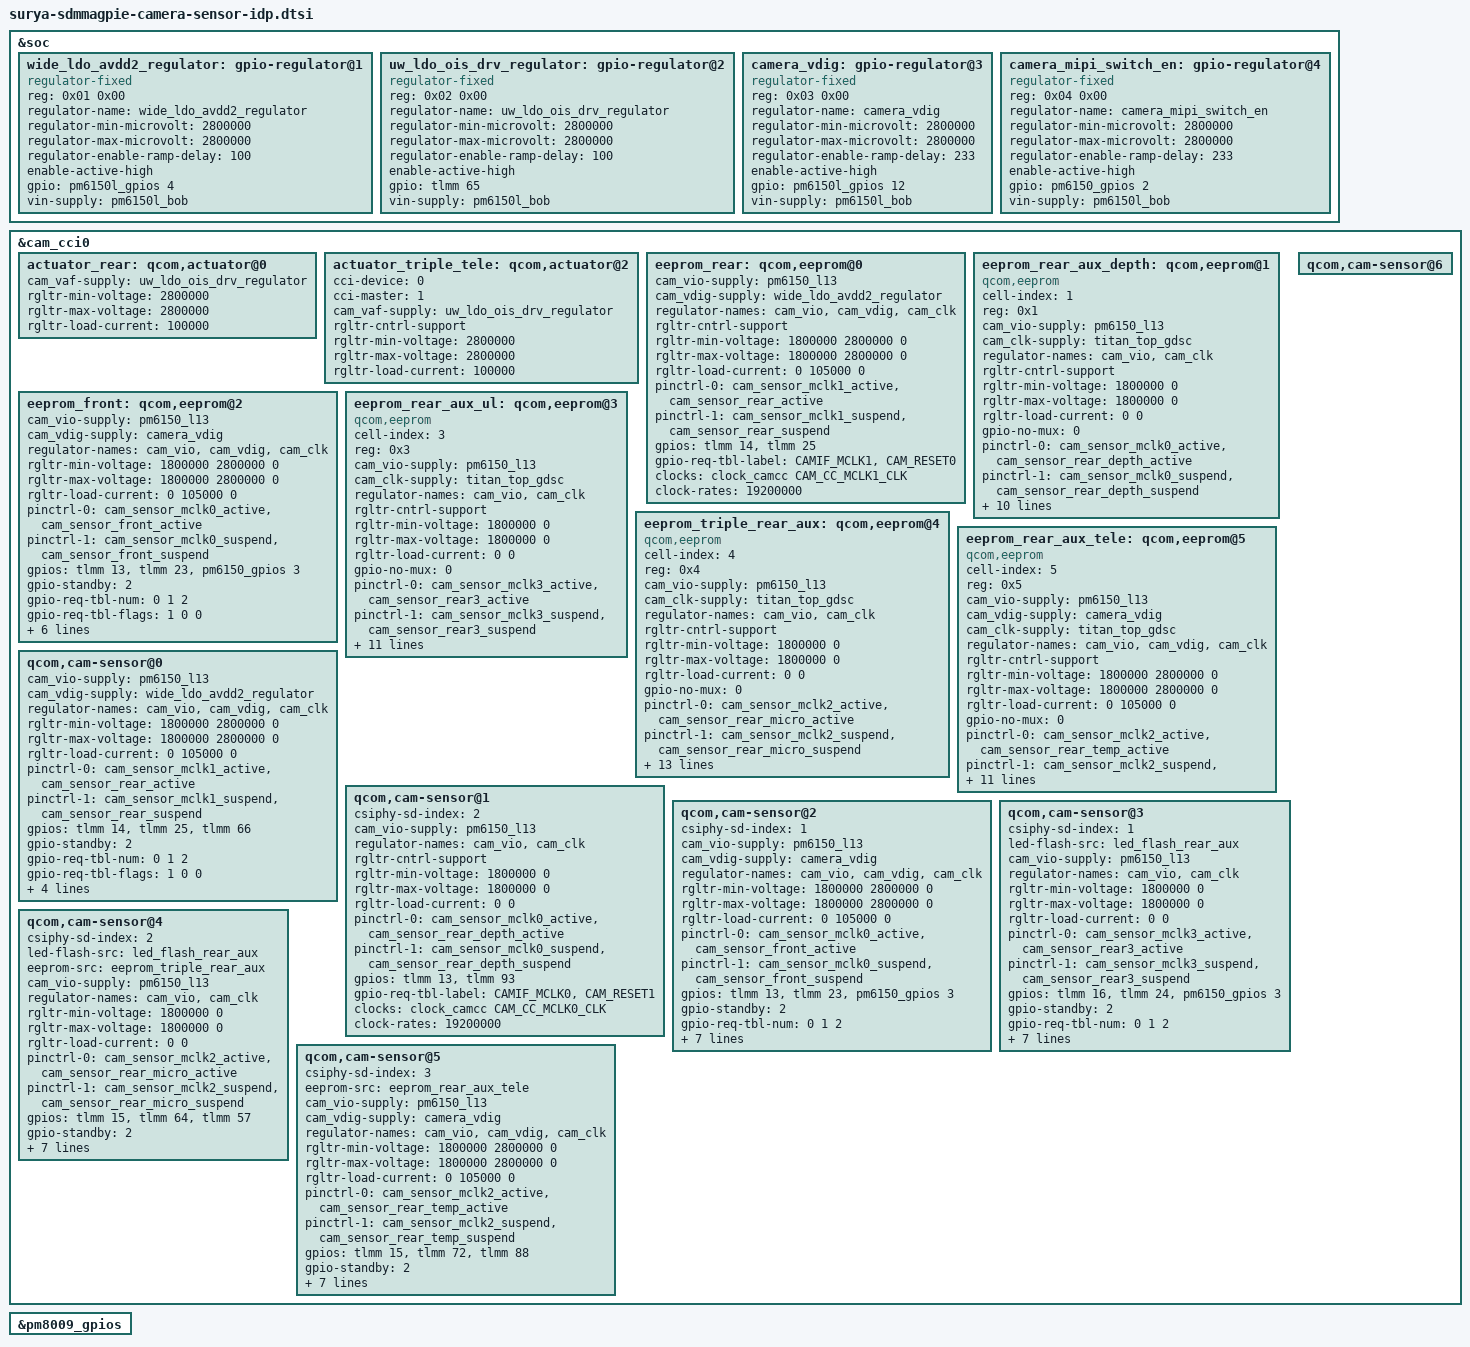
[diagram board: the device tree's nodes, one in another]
&soc {
	wide_ldo_avdd2_regulator: gpio-regulator@1 { //AVDD2 1.8V
		compatible = "regulator-fixed";
		reg = <0x01 0x00>;
		regulator-name = "wide_ldo_avdd2_regulator";
		regulator-min-microvolt = <2800000>;
		regulator-max-microvolt = <2800000>;
		regulator-enable-ramp-delay = <100>;
		enable-active-high;
		gpio = <&pm6150l_gpios 4 0>;
		vin-supply = <&pm6150l_bob>;//pm6150l_s8
	};
/*
	wide_ldo_afvdd_regulator: gpio-regulator@2 { //AFVDD 2.8V
		compatible = "regulator-fixed";
		reg = <0x02 0x00>;
		regulator-name = "wide_ldo_afvdd_regulator";
		regulator-min-microvolt = <2800000>;
		regulator-max-microvolt = <2800000>;
		regulator-enable-ramp-delay = <100>;
		enable-active-high;
		gpio = <&tlmm 66 0>;
		vin-supply = <&pm6150l_bob>;
	};
*/
	uw_ldo_ois_drv_regulator: gpio-regulator@2 { //drvVDD 2.8V
		compatible = "regulator-fixed";
		reg = <0x02 0x00>;
		regulator-name = "uw_ldo_ois_drv_regulator";
		regulator-min-microvolt = <2800000>;
		regulator-max-microvolt = <2800000>;
		regulator-enable-ramp-delay = <100>;
		enable-active-high;
		gpio = <&tlmm 65 0>;
		vin-supply = <&pm6150l_bob>;
	};

	camera_vdig: gpio-regulator@3 {
		compatible = "regulator-fixed";
		reg = <0x03 0x00>;
		regulator-name = "camera_vdig";
		regulator-min-microvolt = <2800000>;
		regulator-max-microvolt = <2800000>;
		regulator-enable-ramp-delay = <233>;
		enable-active-high;
		gpio = <&pm6150l_gpios 12 0>;
		//pinctrl-names = "default";
		//pinctrl-0 = <&cam_sensor_vdig>;
		vin-supply = <&pm6150l_bob>;
	};

	camera_mipi_switch_en: gpio-regulator@4 {
		compatible = "regulator-fixed";
		reg = <0x04 0x00>;
		regulator-name = "camera_mipi_switch_en";
		regulator-min-microvolt = <2800000>;
		regulator-max-microvolt = <2800000>;
		regulator-enable-ramp-delay = <233>;
		enable-active-high;
		gpio = <&pm6150_gpios 2 0>;
		//pinctrl-names = "default";
		//pinctrl-0 = <&cam_mipi_switch_en>;
		vin-supply = <&pm6150l_bob>;
	};
/*
	camera_mipi_switch_sel: gpio-regulator@5 {
		compatible = "regulator-fixed";
		reg = <0x05 0x00>;
		regulator-name = "camera_mipi_switch_sel";
		regulator-min-microvolt = <2800000>;
		regulator-max-microvolt = <2800000>;
		regulator-enable-ramp-delay = <233>;
		enable-active-high;
		gpio = <&pm6150_gpios 3 0>;
		//pinctrl-names = "default";
		//pinctrl-0 = <&cam_mipi_switch_sel>;
		vin-supply = <&pm6150l_bob>;
	};

	tele_ldo_afvdd_regulator: gpio-regulator@5 { //AFVDD 2.8V
		compatible = "regulator-fixed";
		reg = <0x05 0x00>;
		regulator-name = "tele_ldo_afvdd_regulator";
		regulator-min-microvolt = <2800000>;
		regulator-max-microvolt = <2800000>;
		regulator-enable-ramp-delay = <100>;
		enable-active-high;
		gpio = <&tlmm 88 0>;
		vin-supply = <&pm6150l_bob>;
	};
*/
};

&cam_cci0 {

	/delete-node/ eeprom_rear_aux;
	/delete-node/ eeprom_triple_uw;
	/delete-node/ qcom,eeprom@3;
	/delete-node/ qcom,eeprom@4;

	actuator_rear: qcom,actuator@0 {
		cam_vaf-supply = <&uw_ldo_ois_drv_regulator>;
		rgltr-min-voltage = <2800000>;
		rgltr-max-voltage = <2800000>;
		rgltr-load-current = <100000>;
	};

	actuator_triple_tele: qcom,actuator@2 {
		cci-device = <0>;
		cci-master = <1>;
		cam_vaf-supply = <&uw_ldo_ois_drv_regulator>;
		rgltr-cntrl-support;
		rgltr-min-voltage = <2800000>;
		rgltr-max-voltage = <2800000>;
		rgltr-load-current = <100000>;
	};

	eeprom_rear: qcom,eeprom@0 {
		cam_vio-supply = <&pm6150_l13>;//iovdd 1.8v
		cam_vdig-supply = <&wide_ldo_avdd2_regulator>;//dvdd 1.1v
		regulator-names = "cam_vio", "cam_vdig",
			"cam_clk";
		rgltr-cntrl-support;
		rgltr-min-voltage = <1800000 2800000 0>;
		rgltr-max-voltage = <1800000 2800000 0>;
		rgltr-load-current = <0 105000 0>;
		pinctrl-0 = <&cam_sensor_mclk1_active
				&cam_sensor_rear_active>;
		pinctrl-1 = <&cam_sensor_mclk1_suspend
				&cam_sensor_rear_suspend>;
		gpios = <&tlmm 14 0>,
			<&tlmm 25 0>;
		gpio-req-tbl-label = "CAMIF_MCLK1",
					"CAM_RESET0";
		clocks = <&clock_camcc CAM_CC_MCLK1_CLK>;
		clock-rates = <19200000>;

		/delete-property/ cam_vana-supply;
		/delete-property/ cam_vaf-supply;
	};

	eeprom_rear_aux_depth: qcom,eeprom@1 {
		cell-index = <1>;
		reg = <0x1>;
		compatible = "qcom,eeprom";
		cam_vio-supply = <&pm6150_l13>;
		cam_clk-supply = <&titan_top_gdsc>;
		regulator-names = "cam_vio",
			"cam_clk";
		rgltr-cntrl-support;
		rgltr-min-voltage = <1800000 0>;
		rgltr-max-voltage = <1800000 0>;
		rgltr-load-current = <0 0>;
		gpio-no-mux = <0>;
		pinctrl-names = "cam_default", "cam_suspend";
		pinctrl-0 = <&cam_sensor_mclk0_active
				&cam_sensor_rear_depth_active>;
		pinctrl-1 = <&cam_sensor_mclk0_suspend
				&cam_sensor_rear_depth_suspend>;
		gpios = <&tlmm 13 0>,
				<&tlmm 93 0>;
		gpio-reset = <1>;
		gpio-req-tbl-num = <0 1>;
		gpio-req-tbl-flags = <1 0>;
		gpio-req-tbl-label = "CAMIF_MCLK0",
					"CAM_RESET1";
		sensor-mode = <0>;
		cci-master = <1>;
		status = "ok";
		clocks = <&clock_camcc CAM_CC_MCLK0_CLK>;
		clock-names = "cam_clk";
		clock-cntl-level = "turbo";
		clock-rates = <19200000>;
	};

	eeprom_front: qcom,eeprom@2 {
		cam_vio-supply = <&pm6150_l13>;
		cam_vdig-supply = <&camera_vdig>;
		regulator-names = "cam_vio",  "cam_vdig",
			"cam_clk";
		rgltr-min-voltage = <1800000 2800000 0>;
		rgltr-max-voltage = <1800000 2800000 0>;
		rgltr-load-current = <0 105000 0>;
		pinctrl-0 = <&cam_sensor_mclk0_active
				&cam_sensor_front_active>;
		pinctrl-1 = <&cam_sensor_mclk0_suspend
				&cam_sensor_front_suspend>;
		gpios = <&tlmm 13 0>,
			<&tlmm 23 0>,
			<&pm6150_gpios 3 0>;
		gpio-standby = <2>;
		gpio-req-tbl-num = <0 1 2>;
		gpio-req-tbl-flags = <1 0 0>;
		gpio-req-tbl-label = "CAMIF_MCLK0",
					"CAM_RESET4",
					"CAM_SEL";
		cci-device = <0>;
		cci-master = <1>;
		clocks = <&clock_camcc CAM_CC_MCLK0_CLK>;
		clock-rates = <19200000>;

		/delete-property/ cam_vana-supply;
	};

	eeprom_rear_aux_ul: qcom,eeprom@3 {
		cell-index = <3>;
		reg = <0x3>;
		compatible = "qcom,eeprom";
		cam_vio-supply = <&pm6150_l13>;
		cam_clk-supply = <&titan_top_gdsc>;
		regulator-names = "cam_vio",
			"cam_clk";
		rgltr-cntrl-support;
		rgltr-min-voltage = <1800000 0>;
		rgltr-max-voltage = <1800000 0>;
		rgltr-load-current = <0 0>;
		gpio-no-mux = <0>;
		pinctrl-names = "cam_default", "cam_suspend";
		pinctrl-0 = <&cam_sensor_mclk3_active
				&cam_sensor_rear3_active>;
		pinctrl-1 = <&cam_sensor_mclk3_suspend
				&cam_sensor_rear3_suspend>;
		gpios = <&tlmm 16 0>,
			<&tlmm 24 0>;
		gpio-reset = <1>;
		gpio-req-tbl-num = <0 1>;
		gpio-req-tbl-flags = <1 0>;
		gpio-req-tbl-label = "CAMIF_MCLK13",
					"CAM_RESET3";
		sensor-mode = <0>;
		cci-device = <1>;
		cci-master = <0>;
		status = "ok";
		clocks = <&clock_camcc CAM_CC_MCLK3_CLK>;
		clock-names = "cam_clk";
		clock-cntl-level = "turbo";
		clock-rates = <19200000>;
	};

	eeprom_triple_rear_aux: qcom,eeprom@4 {
		cell-index = <4>;
		reg = <0x4>;
		compatible = "qcom,eeprom";
		cam_vio-supply = <&pm6150_l13>;
		cam_clk-supply = <&titan_top_gdsc>;
		regulator-names = "cam_vio",
			"cam_clk";
		rgltr-cntrl-support;
		rgltr-min-voltage = <1800000 0>;
		rgltr-max-voltage = <1800000 0>;
		rgltr-load-current = <0 0>;
		gpio-no-mux = <0>;
		pinctrl-names = "cam_default", "cam_suspend";
		pinctrl-0 = <&cam_sensor_mclk2_active
				&cam_sensor_rear_micro_active>;
		pinctrl-1 = <&cam_sensor_mclk2_suspend
				&cam_sensor_rear_micro_suspend>;
		gpios = <&tlmm 15 0>,
			<&tlmm 64 0>,
			<&tlmm 57 0>;
		gpio-reset = <1>;
		gpio-standby = <2>;
		gpio-req-tbl-num = <0 1 2>;
		gpio-req-tbl-flags = <1 0 0>;
		gpio-req-tbl-label = "CAMIF_MCLK2",
					"CAM_RESET1",
					"CAM_CHIP_EN";
		sensor-mode = <0>;
		cci-device = <1>;
		cci-master = <0>;
		status = "ok";
		clocks = <&clock_camcc CAM_CC_MCLK2_CLK>;
		clock-names = "cam_clk";
		clock-cntl-level = "turbo";
		clock-rates = <19200000>;
	};

	eeprom_rear_aux_tele: qcom,eeprom@5 {
		cell-index = <5>;
		reg = <0x5>;
		compatible = "qcom,eeprom";
		cam_vio-supply = <&pm6150_l13>;
		cam_vdig-supply = <&camera_vdig>;
		cam_clk-supply = <&titan_top_gdsc>;
		regulator-names = "cam_vio", "cam_vdig",
			"cam_clk";
		rgltr-cntrl-support;
		rgltr-min-voltage = <1800000 2800000 0>;
		rgltr-max-voltage = <1800000 2800000 0>;
		rgltr-load-current = <0 105000 0>;
		gpio-no-mux = <0>;
		pinctrl-names = "cam_default", "cam_suspend";
		pinctrl-0 = <&cam_sensor_mclk2_active
				&cam_sensor_rear_temp_active>;
		pinctrl-1 = <&cam_sensor_mclk2_suspend
				&cam_sensor_rear_temp_suspend>;
		gpios = <&tlmm 15 0>,
			<&tlmm 72 0>;
			//<&tlmm 88 0>;
		gpio-reset = <1>;
		//gpio-standby = <4>;//vaf
		gpio-req-tbl-num = <0 1>;
		gpio-req-tbl-flags = <1 0>;
		gpio-req-tbl-label = "CAMIF_MCLK2",
					"CAM_RESET_N";
					//"CAM_STANDBY";//vafs
		sensor-mode = <0>;
		cci-master = <1>;
		status = "ok";
		clocks = <&clock_camcc CAM_CC_MCLK2_CLK>;
		clock-names = "cam_clk";
		clock-cntl-level = "turbo";
		clock-rates = <19200000>;
	};

	qcom,cam-sensor@0 {
		cam_vio-supply = <&pm6150_l13>;//iovdd 1.8v
		cam_vdig-supply = <&wide_ldo_avdd2_regulator>;//dvdd 1.1v
		regulator-names = "cam_vio", "cam_vdig",
			"cam_clk";
		rgltr-min-voltage = <1800000 2800000 0>;
		rgltr-max-voltage = <1800000 2800000 0>;
		rgltr-load-current = <0 105000 0>;
		pinctrl-0 = <&cam_sensor_mclk1_active
				&cam_sensor_rear_active>;
		pinctrl-1 = <&cam_sensor_mclk1_suspend
				&cam_sensor_rear_suspend>;
		gpios = <&tlmm 14 0>,
			<&tlmm 25 0>,
			<&tlmm 66 0>;
		gpio-standby = <2>;
		gpio-req-tbl-num = <0 1 2>;
		gpio-req-tbl-flags = <1 0 0>;
		gpio-req-tbl-label = "CAMIF_MCLK1",
					"CAM_RESET0",
					"CAM_STANDBY";//vafs
		clocks = <&clock_camcc CAM_CC_MCLK1_CLK>;
		clock-rates = <19200000>;

		/delete-property/ cam_vana-supply;
	};

	qcom,cam-sensor@1 {
		csiphy-sd-index = <2>;
		eeprom-src = <&eeprom_rear_aux_depth>;
		cam_vio-supply = <&pm6150_l13>;
		regulator-names = "cam_vio",
			"cam_clk";
		rgltr-cntrl-support;
		rgltr-min-voltage = <1800000 0>;
		rgltr-max-voltage = <1800000 0>;
		rgltr-load-current = <0 0>;
		pinctrl-0 = <&cam_sensor_mclk0_active
				&cam_sensor_rear_depth_active>;
		pinctrl-1 = <&cam_sensor_mclk0_suspend
				&cam_sensor_rear_depth_suspend>;
		gpios = <&tlmm 13 0>,
				<&tlmm 93 0>;
		gpio-req-tbl-label = "CAMIF_MCLK0",
					"CAM_RESET1";
		clocks = <&clock_camcc CAM_CC_MCLK0_CLK>;
		clock-rates = <19200000>;

		/delete-property/ led-flash-src;
		/delete-property/ eeprom-src;
		/delete-property/ actuator-src;
		/delete-property/ cam_vana-supply;
		/delete-property/ cam_vdig-supply;
	};

	qcom,cam-sensor@2 {
		csiphy-sd-index = <1>;
		cam_vio-supply = <&pm6150_l13>;
		cam_vdig-supply = <&camera_vdig>;//gpio12
		regulator-names = "cam_vio",  "cam_vdig",
			"cam_clk";
		rgltr-min-voltage = <1800000 2800000 0>;
		rgltr-max-voltage = <1800000 2800000 0>;
		rgltr-load-current = <0 105000 0>;
		pinctrl-0 = <&cam_sensor_mclk0_active
				&cam_sensor_front_active>;
		pinctrl-1 = <&cam_sensor_mclk0_suspend
				&cam_sensor_front_suspend>;
		gpios = <&tlmm 13 0>,
			<&tlmm 23 0>,
			<&pm6150_gpios 3 0>;
		gpio-standby = <2>;
		gpio-req-tbl-num = <0 1 2>;
		gpio-req-tbl-flags = <1 0 0>;
		gpio-req-tbl-label = "CAMIF_MCLK0",
					"CAM_RESET4",
					"CAM_SEL";
		cci-device = <0>;
		cci-master = <1>;
		clocks = <&clock_camcc CAM_CC_MCLK0_CLK>;
		clock-rates = <19200000>;
	};

	qcom,cam-sensor@3 {
		csiphy-sd-index = <1>;
		led-flash-src = <&led_flash_rear_aux>;
		eeprom-src = <&eeprom_rear_aux_ul>;
		cam_vio-supply = <&pm6150_l13>;
		regulator-names = "cam_vio",
				"cam_clk";
		rgltr-min-voltage = <1800000 0>;
		rgltr-max-voltage = <1800000 0>;
		rgltr-load-current = <0 0>;
		pinctrl-0 = <&cam_sensor_mclk3_active
				&cam_sensor_rear3_active>;
		pinctrl-1 = <&cam_sensor_mclk3_suspend
				&cam_sensor_rear3_suspend>;
		gpios = <&tlmm 16 0>,
				<&tlmm 24 0>,
				<&pm6150_gpios 3 0>;
		gpio-standby = <2>;
		gpio-req-tbl-num = <0 1 2>;
		gpio-req-tbl-flags = <1 0 0>;
		gpio-req-tbl-label = "CAMIF_MCLK3",
					"CAM_RESET3",
					"CAM_SEL";
		cci-device = <1>;
		cci-master = <0>;
		clocks = <&clock_camcc CAM_CC_MCLK3_CLK>;
		clock-rates = <19200000>;

		/delete-property/ eeprom-src;
		/delete-property/ actuator-src;
		/delete-property/ cam_vana-supply;
		/delete-property/ cam_vdig-supply;
	};

	qcom,cam-sensor@4 {
		csiphy-sd-index = <2>;
		led-flash-src = <&led_flash_rear_aux>;
		eeprom-src = <&eeprom_triple_rear_aux>;
		cam_vio-supply = <&pm6150_l13>;
		regulator-names = "cam_vio", /*"cam_vana", "cam_vdig",*/
			"cam_clk";
		rgltr-min-voltage = <1800000 0>;
		rgltr-max-voltage = <1800000 0>;
		rgltr-load-current = <0 0>;
		pinctrl-0 = <&cam_sensor_mclk2_active
				&cam_sensor_rear_micro_active>;
		pinctrl-1 = <&cam_sensor_mclk2_suspend
				&cam_sensor_rear_micro_suspend>;
		gpios = <&tlmm 15 0>,
			<&tlmm 64 0>,
			<&tlmm 57 0>;
		gpio-standby = <2>;//chip-en
		gpio-req-tbl-num = <0 1 2>;
		gpio-req-tbl-flags = <1 0 0>;
		gpio-req-tbl-label = "CAMIF_MCLK2",
					"CAM_RESET1",
					"CAM_CHIP_EN";
		cci-device = <1>;
		clocks = <&clock_camcc CAM_CC_MCLK2_CLK>;
		clock-rates = <19200000>;

		/delete-property/ actuator-src;
		/delete-property/ cam_vana-supply;
		/delete-property/ cam_vdig-supply;
	};

	qcom,cam-sensor@5 {
		csiphy-sd-index = <3>;
		eeprom-src = <&eeprom_rear_aux_tele>;
		cam_vio-supply = <&pm6150_l13>;
		cam_vdig-supply = <&camera_vdig>;
		regulator-names = "cam_vio", "cam_vdig",
			"cam_clk";
		rgltr-min-voltage = <1800000 2800000 0>;
		rgltr-max-voltage = <1800000 2800000 0>;
		rgltr-load-current = <0 105000 0>;
		pinctrl-0 = <&cam_sensor_mclk2_active
				&cam_sensor_rear_temp_active>;
		pinctrl-1 = <&cam_sensor_mclk2_suspend
				&cam_sensor_rear_temp_suspend>;
		gpios = <&tlmm 15 0>,
			<&tlmm 72 0>,
			<&tlmm 88 0>;
		gpio-standby = <2>;//vaf1
		gpio-req-tbl-num = <0 1 2>;
		gpio-req-tbl-flags = <1 0 0>;
		gpio-req-tbl-label = "CAMIF_MCLK2",
					"CAM_RESET_N",
					"CAM_STANDBY";//vafs
		cci-master = <1>;
		clocks = <&clock_camcc CAM_CC_MCLK2_CLK>;
		clock-rates = <19200000>;

		/delete-property/ led-flash-src;
		/delete-property/ actuator-src;
		/delete-property/ cam_vana-supply;
	};

	qcom,cam-sensor@6 {
		/delete-property/ eeprom-src;
	};
};

&pm8009_gpios {
	/delete-node/ cam_sensor_rear_active;
	/delete-node/ cam_sensor_rear_suspend;
	/delete-node/ cam_sensor_rear2_active;
	/delete-node/ cam_sensor_rear2_suspend;
	/delete-node/ cam_sensor_front_active;
	/delete-node/ cam_sensor_front_suspend;
};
